# MCAN_ECC_AGGR_24018000h register map
Vendor: Texas Instruments
Peripheral module from a debugger description file (folder am62D).
Registers are 32-bit, access not given, reset 0x0 unless marked. A register's access mark holds for its fields unless they carry their own. Offsets are as the file gives them; lines under a group give offsets from that group; [hi:lo] are bit positions; {n}, {i} and the like mark numbered series; 'fields as' and 'values as' point back to an identical list; <NAME> marks a mode.

## ecc_aggr
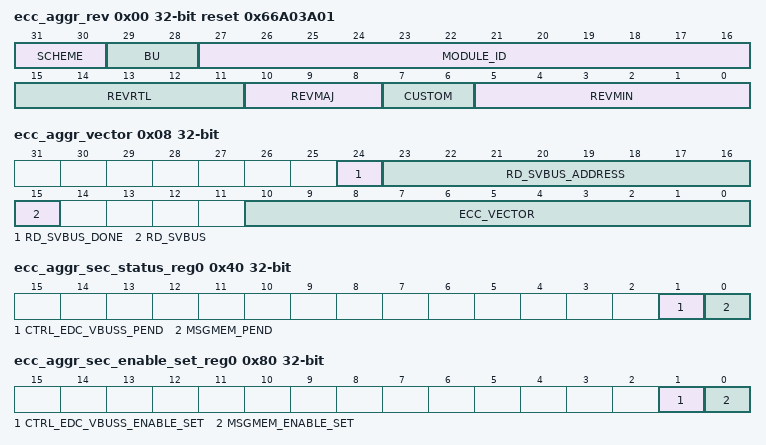
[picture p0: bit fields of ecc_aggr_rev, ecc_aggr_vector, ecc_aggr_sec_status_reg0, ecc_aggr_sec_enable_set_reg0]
0x00 ecc_aggr_rev ro reset 0x66A03A01 — Revision parameters
  [31:30] SCHEME
  [29:28] BU — Business Unit
  [27:16] MODULE_ID
  [15:11] REVRTL — RTL Version
  [10:8] REVMAJ — Major Version
  [7:6] CUSTOM — Custom Version
  [5:0] REVMIN — Minor Version
0x08 ecc_aggr_vector — ECC Vector Register
  [24] RD_SVBUS_DONE — Read Done Status to indicate if read on the serial ECC interface is complete, write of any value will clear this bit. (access R/W1TC)
  [23:16] RD_SVBUS_ADDRESS rw — Read Address
  [15] RD_SVBUS — Read Trigger Write 1h to trigger a read on the serial ECC interface. (access R/W1TS)
  [10:0] ECC_VECTOR rw — ECC RAM ID Value written to select the corresponding ECC RAM for control or status.
0x0C ecc_aggr_stat ro reset 0x2 — Misc Status
  [10:0] NUM_RAMS — Number of RAMs Indicates the number of RAMs serviced by the ECC Aggregator.
0x10 ecc_aggr_reserved_svbus_j rw — Reference other documents that contain the ECC RAM wrapper and EDC controller serial vbus register sets.
  [31:0] DATA — Serial VBUS register data
0x3C ecc_aggr_sec_eoi_reg — EOI Register
  [0] EOI_WR — Single Error Correction End Of Interrupt (SEC EOI) (access R/W1TS)
0x40 ecc_aggr_sec_status_reg0 — Interrupt Status Register 0
  [1] CTRL_EDC_VBUSS_PEND — Interrupt Pending Status for CTRL_EDC_VBUSS_PEND (access R/W1TS)
  [0] MSGMEM_PEND — Interrupt Pending Status for MSGMEM_PEND (access R/W1TS)
0x80 ecc_aggr_sec_enable_set_reg0 — Interrupt Enable Set Register 0
  [1] CTRL_EDC_VBUSS_ENABLE_SET — Interrupt Enable Set for CTRL_EDC_VBUSS_PEND (access R/W1TS)
  [0] MSGMEM_ENABLE_SET — Interrupt Enable Set for MSGMEM_PEND (access R/W1TS)
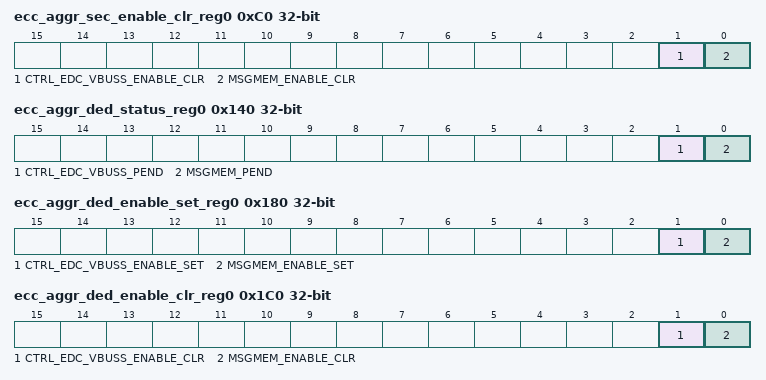
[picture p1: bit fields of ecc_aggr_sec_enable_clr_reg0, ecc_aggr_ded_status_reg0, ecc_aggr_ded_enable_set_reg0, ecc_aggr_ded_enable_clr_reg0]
0xC0 ecc_aggr_sec_enable_clr_reg0 — Interrupt Enable Clear Register 0
  [1] CTRL_EDC_VBUSS_ENABLE_CLR — Interrupt Enable Clear for CTRL_EDC_VBUSS_PEND (access R/W1TC)
  [0] MSGMEM_ENABLE_CLR — Interrupt Enable Clear for MSGMEM_PEND (access R/W1TC)
0x13C ecc_aggr_ded_eoi_reg — EOI Register
  [0] EOI_WR — Double Error Correction End Of Interrupt (DED EOI) (access R/W1TS)
0x140 ecc_aggr_ded_status_reg0 — Interrupt Status Register 0
  fields as ecc_aggr_sec_status_reg0
0x180 ecc_aggr_ded_enable_set_reg0 — Interrupt Enable Set Register 0
  fields as ecc_aggr_sec_enable_set_reg0
0x1C0 ecc_aggr_ded_enable_clr_reg0 — Interrupt Enable Clear Register 0
  fields as ecc_aggr_sec_enable_clr_reg0
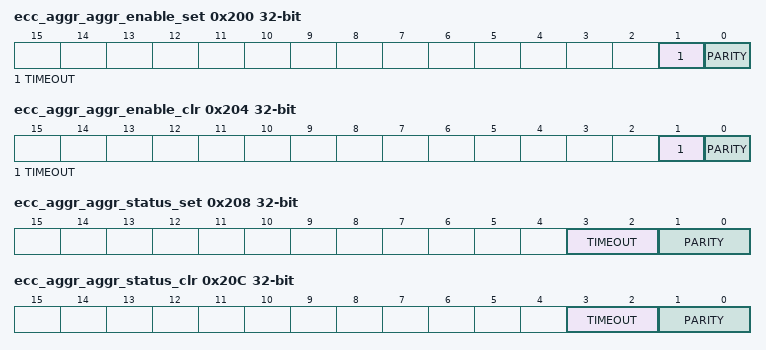
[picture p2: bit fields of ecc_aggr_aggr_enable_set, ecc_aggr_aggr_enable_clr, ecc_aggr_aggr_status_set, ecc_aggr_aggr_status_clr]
0x200 ecc_aggr_aggr_enable_set — AGGR interrupt enable set Register
  [1] TIMEOUT — Interrupt Enable Set for Serial ECC Interface Timeout Errors (access R/W1TS)
  [0] PARITY — Interrupt Enable Set for Parity Errors (access R/W1TS)
0x204 ecc_aggr_aggr_enable_clr — AGGR interrupt enable clear Register
  [1] TIMEOUT — Interrupt Enable Clear for Serial ECC Interface Timeout Errors (access R/W1TC)
  [0] PARITY — Interrupt Enable Clear for Parity Errors (access R/W1TC)
0x208 ecc_aggr_aggr_status_set — AGGR interrupt status set Register
  [3:2] TIMEOUT — Interrupt Status Set for Serial ECC Interface Timeout Errors (access R/WI)
  [1:0] PARITY — Interrupt Status Set for Parity Errors (access R/WI)
0x20C ecc_aggr_aggr_status_clr — AGGR interrupt status clear Register
  [3:2] TIMEOUT — Interrupt Status Clear for Serial ECC Interface Timeout Errors (access R/WD)
  [1:0] PARITY — Interrupt Status Clear for Parity Errors (access R/WD)
